AUTOSAR XML (schema 4-2-2)
package /ComponentTypes
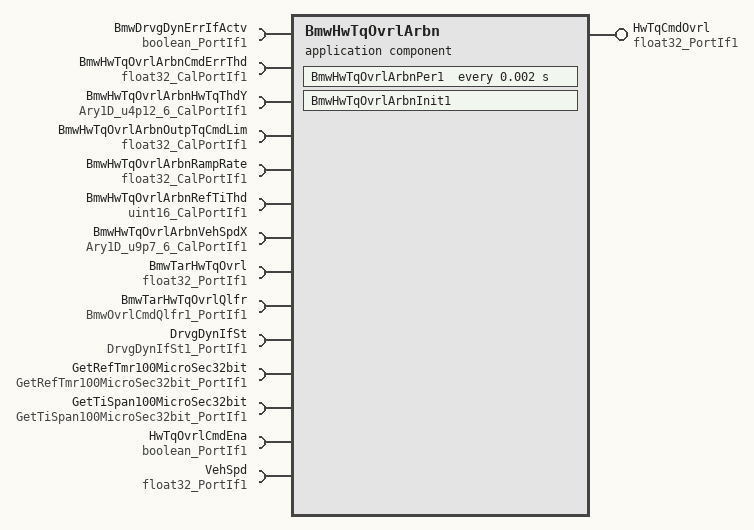
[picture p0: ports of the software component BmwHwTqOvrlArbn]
  application sw component type BmwHwTqOvrlArbn
    provide port HwTqCmdOvrl: nonqueued-sender-com-spec{data-element=Val, init-value=0}, provided-interface=float32_PortIf1
    14 x require port:
      BmwDrvgDynErrIfActv: nonqueued-receiver-com-spec{data-element=Logl, filter=data-filter-type=ALWAYS, init-value=0}, required-interface=boolean_PortIf1
      BmwHwTqOvrlArbnCmdErrThd: parameter-require-com-spec{init-value=0.1, parameter=Val}, required-interface=float32_CalPortIf1
      BmwHwTqOvrlArbnHwTqThdY: parameter-require-com-spec{init-value=[12288, 12288, 8192, 4096, 0, 0], parameter=Ary1D}, required-interface=Ary1D_u4p12_6_CalPortIf1
      BmwHwTqOvrlArbnOutpTqCmdLim: parameter-require-com-spec{init-value=3, parameter=Val}, required-interface=float32_CalPortIf1
      BmwHwTqOvrlArbnRampRate: parameter-require-com-spec{init-value=10, parameter=Val}, required-interface=float32_CalPortIf1
      BmwHwTqOvrlArbnRefTiThd: parameter-require-com-spec{init-value=500, parameter=Val}, required-interface=uint16_CalPortIf1
      BmwHwTqOvrlArbnVehSpdX: parameter-require-com-spec{init-value=[0, 1280, 2560, 6400, 12800, 25600], parameter=Ary1D}, required-interface=Ary1D_u9p7_6_CalPortIf1
      BmwTarHwTqOvrl: nonqueued-receiver-com-spec{data-element=Val, filter=data-filter-type=ALWAYS, init-value=0}, required-interface=float32_PortIf1
      BmwTarHwTqOvrlQlfr: nonqueued-receiver-com-spec{data-element=Val, filter=data-filter-type=ALWAYS, init-value=15}, required-interface=BmwOvrlCmdQlfr1_PortIf1
      DrvgDynIfSt: nonqueued-receiver-com-spec{data-element=Val, filter=data-filter-type=ALWAYS, init-value=128}, required-interface=DrvgDynIfSt1_PortIf1
      GetRefTmr100MicroSec32bit: client-com-spec=Oper, required-interface=GetRefTmr100MicroSec32bit_PortIf1
      GetTiSpan100MicroSec32bit: client-com-spec=Oper, required-interface=GetTiSpan100MicroSec32bit_PortIf1
      HwTqOvrlCmdEna: nonqueued-receiver-com-spec{data-element=Logl, filter=data-filter-type=ALWAYS, init-value=1}, required-interface=boolean_PortIf1
      VehSpd: nonqueued-receiver-com-spec{data-element=Val, filter=data-filter-type=ALWAYS, init-value=0}, required-interface=float32_PortIf1
    behavior BmwHwTqOvrlArbn_InternalBehavior
      ar-typed-per-instance-memorys:
        6 x data, all with sw-calibration-access=READ-ONLY:
          ArbdHwTqOvrlLtch: type=float32
          FctlErrActv: type=boolean
          FctlErrTmr: type=uint32
          HwTqOvrlScaFacStVari: type=float32
          PrevArbdHwTqOvrl: type=float32
          PrevFctlErr: type=boolean
      init event BmwHwTqOvrlArbn_InitEvent: start-on-event=BmwHwTqOvrlArbnInit1
      timing event TMT_BmwHwTqOvrlArbnPer1: start-on-event=BmwHwTqOvrlArbnPer1, period=0.002
      port-api-options:
        enable-take-address=false, error-handling=NO-TRANSFORMER-ERROR-HANDLING, indirect-api=false, port=BmwDrvgDynErrIfActv
        enable-take-address=false, error-handling=NO-TRANSFORMER-ERROR-HANDLING, indirect-api=false, port=BmwHwTqOvrlArbnCmdErrThd
        enable-take-address=false, error-handling=NO-TRANSFORMER-ERROR-HANDLING, indirect-api=false, port=BmwHwTqOvrlArbnHwTqThdY
        enable-take-address=false, error-handling=NO-TRANSFORMER-ERROR-HANDLING, indirect-api=false, port=BmwHwTqOvrlArbnOutpTqCmdLim
        enable-take-address=false, error-handling=NO-TRANSFORMER-ERROR-HANDLING, indirect-api=false, port=BmwHwTqOvrlArbnRampRate
        enable-take-address=false, error-handling=NO-TRANSFORMER-ERROR-HANDLING, indirect-api=false, port=BmwHwTqOvrlArbnRefTiThd
        enable-take-address=false, error-handling=NO-TRANSFORMER-ERROR-HANDLING, indirect-api=false, port=BmwHwTqOvrlArbnVehSpdX
        enable-take-address=false, error-handling=NO-TRANSFORMER-ERROR-HANDLING, indirect-api=false, port=BmwTarHwTqOvrl
        enable-take-address=false, error-handling=NO-TRANSFORMER-ERROR-HANDLING, indirect-api=false, port=BmwTarHwTqOvrlQlfr
        enable-take-address=false, error-handling=NO-TRANSFORMER-ERROR-HANDLING, indirect-api=false, port=DrvgDynIfSt
        enable-take-address=false, error-handling=NO-TRANSFORMER-ERROR-HANDLING, indirect-api=false, port=GetRefTmr100MicroSec32bit
        enable-take-address=false, error-handling=NO-TRANSFORMER-ERROR-HANDLING, indirect-api=false, port=GetTiSpan100MicroSec32bit
        enable-take-address=false, error-handling=NO-TRANSFORMER-ERROR-HANDLING, indirect-api=false, port=HwTqCmdOvrl
        enable-take-address=false, error-handling=NO-TRANSFORMER-ERROR-HANDLING, indirect-api=false, port=HwTqOvrlCmdEna
        enable-take-address=false, error-handling=NO-TRANSFORMER-ERROR-HANDLING, indirect-api=false, port=VehSpd
      runnable BmwHwTqOvrlArbnInit1
      runnable BmwHwTqOvrlArbnPer1
        data-receive-point-by-arguments:
          6 x access:
            REC_BmwDrvgDynErrIfActv_Logl: accessed-variable=BmwDrvgDynErrIfActv.Logl
            REC_BmwTarHwTqOvrl_Val: accessed-variable=BmwTarHwTqOvrl.Val
            REC_BmwTarHwTqOvrlQlfr_Val: accessed-variable=BmwTarHwTqOvrlQlfr.Val
            REC_DrvgDynIfSt_Val: accessed-variable=DrvgDynIfSt.Val
            REC_HwTqOvrlCmdEna_Logl: accessed-variable=HwTqOvrlCmdEna.Logl
            REC_VehSpd_Val: accessed-variable=VehSpd.Val
        data-send-points:
          access SEND_HwTqCmdOvrl_Val: accessed-variable=HwTqCmdOvrl.Val
        sync call SC_GetRefTmr100MicroSec32bit_Oper: operation=GetRefTmr100MicroSec32bit.Oper, timeout=0
        sync call SC_GetTiSpan100MicroSec32bit_Oper: operation=GetTiSpan100MicroSec32bit.Oper, timeout=0
  swc implementation BmwHwTqOvrlArbn_Implementation: behavior=BmwHwTqOvrlArbn_InternalBehavior
    code-descriptors:
      code Default: artifact-descriptors=autosar-engineering-object={short-label=Default, category=SWSRC}
